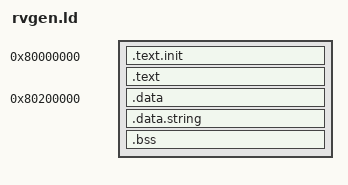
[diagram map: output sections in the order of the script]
OUTPUT_ARCH( "riscv" )
ENTRY(_start)

SECTIONS
{
  . = 0x80000000;
  .text.init : { *(.text.init) }
  .text : { *(.text) }
  . = ALIGN(0x1000);
  . = 0x80200000;
  .data : { *(.data) }
  .data.string : { *(.data.string)}
  .bss : { *(.bss) }
  _end = .;
}

